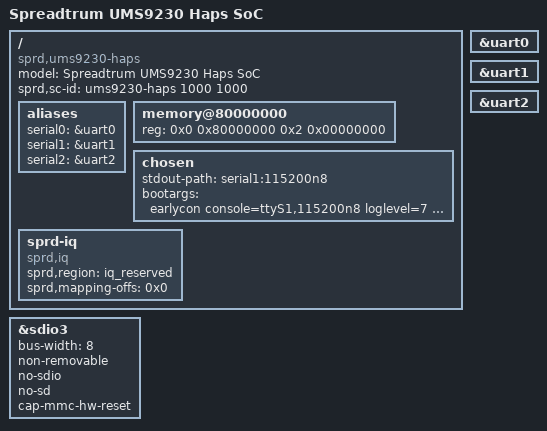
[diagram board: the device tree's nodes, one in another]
// SPDX-License-Identifier: GPL-2.0-only
/*
 * Unisoc Qogirl6 platform DTS file
 *
 * Copyright (C) 2020, Unisoc Inc.
 */

/dts-v1/;

#include <dt-bindings/gpio/gpio.h>
#include "ums9230-haps.dtsi"
#include "ums9230-haps-mach.dtsi"
#include "ums9230-haps-modem.dtsi"

/ {
	model = "Spreadtrum UMS9230 Haps SoC";

	compatible = "sprd,ums9230-haps";

	sprd,sc-id = "ums9230-haps 1000 1000";

	aliases {
		serial0 = &uart0;
		serial1 = &uart1;
		serial2 = &uart2;
	};

	memory@80000000 {
		device_type = "memory";
		reg = <0x0 0x80000000 0x2 0x00000000>;
	};

	chosen: chosen {
		stdout-path = "serial1:115200n8";
		bootargs = "earlycon console=ttyS1,115200n8 loglevel=7 init=/init root=/dev/ram0 rw printk.devkmsg=on andooidboot.selinux=permissive";
	};

	sprd-iq {
		compatible = "sprd,iq";
		sprd,region = <&iq_reserved>;
		sprd,mapping-offs = <0x0>;
	};
};

&uart0 {
	status = "okay";
};

&uart1 {
	status = "okay";
};

&uart2 {
	status = "okay";
};

&sdio3 {
	bus-width = <8>;
	non-removable;
	no-sdio;
	no-sd;
	cap-mmc-hw-reset;
	status = "okay";
};

